# GD32A72_A74x register map
File version: 1.0
CPU: CM7 r2p1, little endian, MPU, FPU, DSP, 4 interrupt priority bits
Registers are 32-bit, read-write, reset 0x0 unless marked. A register's access mark holds for its fields unless they carry their own. Offsets are from the block's base; [hi:lo] are bit positions.

## LIN0 — Local Interconnect Network
Base 0x40010800
Same registers: LIN6 0x40008800, LIN7 0x40008C00, LIN8 0x40009000, LIN9 0x40009400, LIN10 0x40009800, LIN11 0x40009C00, LIN1 0x40010C00, LIN2 0x40011000, LIN3 0x40011400, LIN4 0x40011800, LIN5 0x40011C00
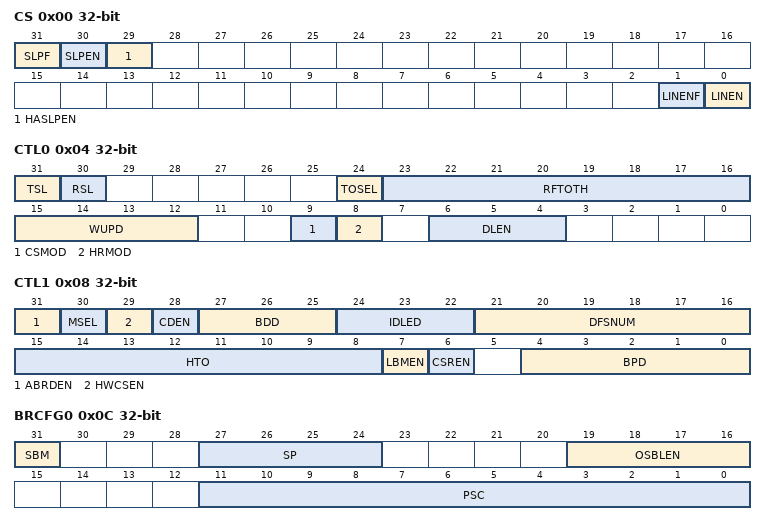
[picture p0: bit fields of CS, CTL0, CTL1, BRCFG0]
0x00 CS access per field — Control and status register
  [31] SLPF ro — LIN sleep flag
  [30] SLPEN rw — LIN sleep enable
  [29] HASLPEN rw — hardware automatic sleep enable
  [1] LINENF ro — LIN enable flag
  [0] LINEN rw — LIN enable
0x04 CTL0 access per field — Control register 0
  [31] TSL ro — Transmit signal level
  [30] RSL ro — Receive signal level
  [24] TOSEL rw — Timeout select
  [23:16] RFTOTH rw — Response / frame timeout threshold
  [15:12] WUPD rw — Wakeup pulse duration
  [9] CSMOD rw — Checksum mode
  [8] HRMOD rw — Header and response mode
  [6:4] DLEN rw — Data length of a frame
0x08 CTL1 — Control register 1
  [31] ABRDEN — Automatic baud rate detection enable
  [30] MSEL — LIN mode seletct
  [29] HWCSEN — Hardware checksum enable
  [28] CDEN — Collision detection enable
  [27:25] BDD — Break delimiter duration
  [24:22] IDLED — Idle duration
  [21:16] DFSNUM — Digital filter sample number
  [15:8] HTO — Header timeout
  [7] LBMEN — Loopback mode enable
  [6] CSREN — Checksum receive enable
  [4:0] BPD — Break pulse duration
0x0C BRCFG0 — Baud rate configure register 0
  [31] SBM — Sample bit method
  [27:24] SP — Sample point
  [19:16] OSBLEN — Oversampling bit length
  [11:0] PSC — Prescaler
0x10 BRCFG1 reset 0x1 — Baud rate configure register 1
  [23:0] DIV — Division
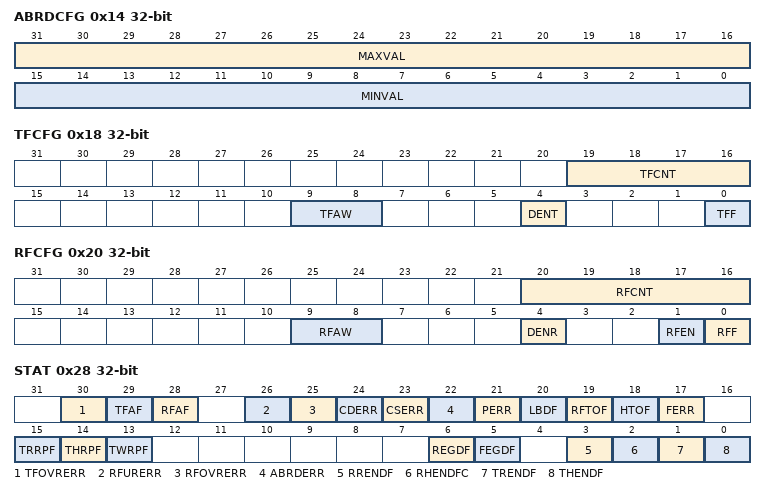
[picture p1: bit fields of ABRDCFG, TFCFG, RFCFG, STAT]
0x14 ABRDCFG — Automatic baud rate detection configure register
  [31:16] MAXVAL — Maximum value
  [15:0] MINVAL — Minimum value
0x18 TFCFG access per field — Transmit FIFO configuration register
  [19:16] TFCNT ro — Transmit FIFO counter
  [9:8] TFAW rw — Transmit FIFO access width
  [4] DENT rw — DMA enable for transmission
  [0] TFF wo — Transmit FIFO flush
0x1C TDATA wo — Transmit data register
  [31:0] TDATA — Transmit data
0x20 RFCFG access per field — Receive FIFO configuration register
  [20:16] RFCNT ro — Receive FIFO count
  [9:8] RFAW rw — Receive FIFO access width
  [4] DENR rw — DMA enable for reception
  [1] RFEN rw — Receive FIFO enable
  [0] RFF wo — Receive FIFO flush
0x24 RDATA ro — Receive data register
  [31:0] RDATA — Receive data
0x28 STAT ro — Status register
  [30] TFOVRERR — Transmit FIFO overrun error flag
  [29] TFAF — Transmit FIFO available flag
  [28] RFAF — Receive FIFO available flag
  [26] RFURERR — Receive FIFO underrun error flag
  [25] RFOVRERR — Receive FIFO overrun error flag
  [24] CDERR — Collision detection error flag
  [23] CSERR — Checksum error flag
  [22] ABRDERR — Automatic baud detection error flag
  [21] PERR — Parity error flag
  [20] LBDF — LIN break detected flag
  [19] RFTOF — Response / frame timeout flag
  [18] HTOF — Header timeout flag
  [17] FERR — Frame error flag
  [15] TRRPF — Transmit response request pending flag
  [14] THRPF — Transmit header request pending flag
  [13] TWRPF — Transmit wake request pending flag
  [6] REGDF — Rising edge detect flag
  [5] FEGDF — Falling edge detect flag
  [3] RRENDF — Receive response end flag
  [2] RHENDFC — Receive header end flag
  [1] TRENDF — Transmit response end flag
  [0] THENDF — Transmit header end flag
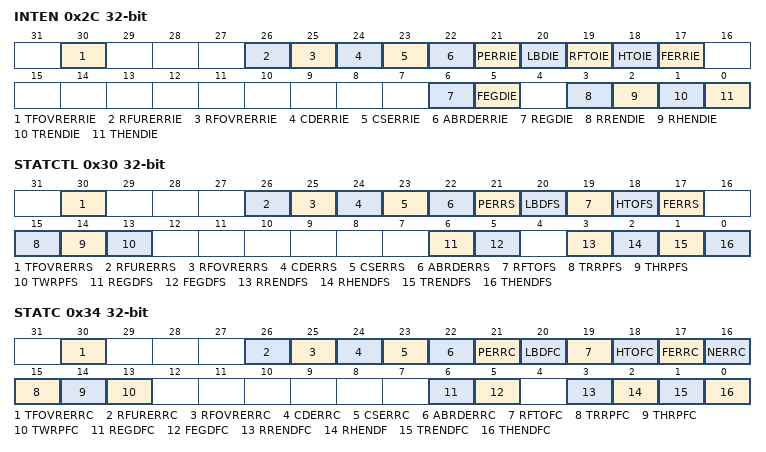
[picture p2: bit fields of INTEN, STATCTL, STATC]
0x2C INTEN — Interrupt enable register
  [30] TFOVRERRIE — Transmit FIFO overrun error interrupt enable
  [26] RFURERRIE — Receive FIFO underrun error interrupt enable
  [25] RFOVRERRIE — Receive FIFO overrun error interrupt enable
  [24] CDERRIE — Collision detection error interrupt enable
  [23] CSERRIE — Checksum error interrupt enable
  [22] ABRDERRIE — Automatic baud detection error interrupt enable
  [21] PERRIE — Parity error interrupt enable
  [20] LBDIE — LIN break detected interrupt enable
  [19] RFTOIE — Response timeout interrupt enable
  [18] HTOIE — Header timeout interrupt enable
  [17] FERRIE — Frame error interrupt enable
  [6] REGDIE — Rising edge detect interrupt enable
  [5] FEGDIE — Falling edge detect interrupt enable
  [3] RRENDIE — Receive response complete interrupt enable
  [2] RHENDIE — Receive header complete interrupt enable
  [1] TRENDIE — Transmit response complete interrupt enable
  [0] THENDIE — Transmit header complete interrupt enable
0x30 STATCTL wo — Status control register
  [30] TFOVRERRS — Transmit FIFO overrun error flag set
  [26] RFURERRS — Receive FIFO underrun error flag set
  [25] RFOVRERRS — Receive FIFO overrun error flag set
  [24] CDERRS — Collision detection error flag set
  [23] CSERRS — Checksum error flag set
  [22] ABRDERRS — Automatic baud detection error flag set
  [21] PERRS — Parity error flag set
  [20] LBDFS — LIN break detected flag set
  [19] RFTOFS — Response timeout flag set
  [18] HTOFS — Header timeout flag set
  [17] FERRS — Frame error flag set
  [15] TRRPFS — Transmit response request pending flag set
  [14] THRPFS — Transmit header request pending flag set
  [13] TWRPFS — Transmit wake request pending flag set
  [6] REGDFS — Rising edge detect flag set
  [5] FEGDFS — Falling edge detect flag set
  [3] RRENDFS — Receive response complete flag set
  [2] RHENDFS — Receive header complete flag set
  [1] TRENDFS — Transmit response complete flag set
  [0] THENDFS — Transmit header complete flag set
0x34 STATC wo — Status clear register
  [30] TFOVRERRC — Transmit FIFO overrun error flag clear
  [26] RFURERRC — Receive FIFO underrun error flag clear
  [25] RFOVRERRC — Receive FIFO overrun error flag clear
  [24] CDERRC — Collision detection error flag clear
  [23] CSERRC — Checksum error flag clear
  [22] ABRDERRC — Automatic baud detection error flag clear
  [21] PERRC — Parity error flag clear
  [20] LBDFC — LIN break detected flag clear
  [19] RFTOFC — Response timeout flag clear
  [18] HTOFC — Header timeout flag clear
  [17] FERRC — Frame error flag clear
  [16] NERRC — Noise error flag clear
  [15] TRRPFC — Transmit response request pending flag clear
  [14] THRPFC — Transmit header request pending flag clear
  [13] TWRPFC — Transmit wake request pending flag clear
  [6] REGDFC — Rising edge detect flag clear
  [5] FEGDFC — Falling edge detect flag clear
  [3] RRENDFC — Receive response complete flag clear
  [2] RHENDF — Receive header complete flag clear
  [1] TRENDFC — Transmit response complete flag clear
  [0] THENDFC — Transmit header complete flag clear
0x38 ABRD ro — Automatic baud rate detection register
  [23:0] SYNCMV — Sync field measured value
0x3C WUTHCFG — Wakeup detection threshold configure register
  [31:0] WUTH — These bits define the threshold of the detection of wakeup pulse width, it is related to the frequency of CK_LINx
